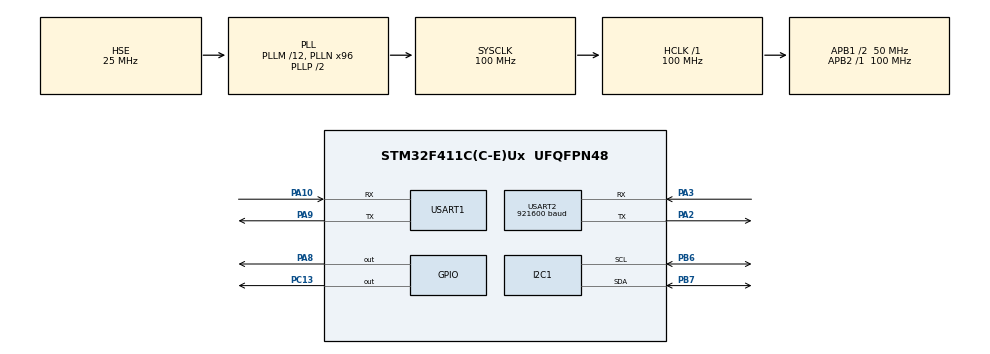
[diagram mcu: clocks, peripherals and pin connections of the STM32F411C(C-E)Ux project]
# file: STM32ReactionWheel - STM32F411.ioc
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I2C1.I2C_Mode=I2C_Fast
Mcu.Family=STM32F4
Mcu.Name=STM32F411C(C-E)Ux
Mcu.Package=UFQFPN48
NVIC.PriorityGroup=NVIC_PRIORITYGROUP_4
PA10.Mode=Asynchronous
PA10.Signal=USART1_RX
PA13.Mode=Trace_Asynchronous_SW
PA13.Signal=SYS_JTMS-SWDIO
PA14.Mode=Trace_Asynchronous_SW
PA14.Signal=SYS_JTCK-SWCLK
PA2.Mode=Asynchronous
PA2.Signal=USART2_TX
PA3.Mode=Asynchronous
PA3.Signal=USART2_RX
PA8.Signal=GPIO_Output
PA9.Mode=Asynchronous
PA9.Signal=USART1_TX
PB3.Mode=Trace_Asynchronous_SW
PB3.Signal=SYS_JTDO-SWO
PB6.Mode=I2C
PB6.Signal=I2C1_SCL
PB7.Mode=I2C
PB7.Signal=I2C1_SDA
PC13-ANTI_TAMP.GPIO_ModeDefaultOutputPP=GPIO_MODE_OUTPUT_OD
PC13-ANTI_TAMP.GPIO_PuPd=GPIO_NOPULL
PC13-ANTI_TAMP.PinState=GPIO_PIN_SET
PC13-ANTI_TAMP.Signal=GPIO_Output
PH0\ -\ OSC_IN.Mode=HSE-External-Oscillator
PH0\ -\ OSC_IN.Signal=RCC_OSC_IN
PH1\ -\ OSC_OUT.Mode=HSE-External-Oscillator
PH1\ -\ OSC_OUT.Signal=RCC_OSC_OUT
ProjectManager.HeapSize=0x200
ProjectManager.StackSize=0x400
ProjectManager.TargetToolchain=STM32CubeIDE
RCC.48MHZClocksFreq_Value=50000000
RCC.AHBFreq_Value=100000000
RCC.APB1CLKDivider=RCC_HCLK_DIV2
RCC.APB1Freq_Value=50000000
RCC.APB1TimFreq_Value=100000000
RCC.APB2Freq_Value=100000000
RCC.APB2TimFreq_Value=100000000
RCC.CortexFreq_Value=100000000
RCC.HCLKFreq_Value=100000000
RCC.HSE_VALUE=25000000
RCC.HSI_VALUE=16000000
RCC.LSE_VALUE=32768
RCC.PLLM=12
RCC.PLLN=96
RCC.PLLSourceVirtual=RCC_PLLSOURCE_HSE
RCC.SYSCLKFreq_VALUE=100000000
RCC.SYSCLKSource=RCC_SYSCLKSOURCE_PLLCLK
RCC.VCOOutputFreq_Value=200000000
STMicroelectronics.X-CUBE-ALGOBUILD.1.3.0.LibraryCcDSPOoLibraryJjDSPOoLibrary=true
USART1.VirtualMode=VM_ASYNC
USART2.BaudRate=921600
USART2.Mode=MODE_TX
USART2.VirtualMode=VM_ASYNC
VP_STMicroelectronics.X-CUBE-ALGOBUILD_VS_DSPOoLibraryJjLibrary_1.3.0_1.3.0.Mode=DSPOoLibraryJjLibrary
board=custom

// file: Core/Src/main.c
/* USER CODE BEGIN Header */
/**
  ******************************************************************************
  * @file           : main.c
  * @brief          : Main program body
  ******************************************************************************
  * @attention
  *
  * Copyright (c) 2023 STMicroelectronics.
  * All rights reserved.
  *
  * This software is licensed under terms that can be found in the LICENSE file
  * in the root directory of this software component.
  * If no LICENSE file comes with this software, it is provided AS-IS.
  *
  ******************************************************************************
  */
/* USER CODE END Header */
#include "main.h"

/* USER CODE BEGIN Includes */
#include "Application.h"
/* USER CODE END Includes */

I2C_HandleTypeDef hi2c1;

UART_HandleTypeDef huart1;
UART_HandleTypeDef huart2;

void SystemClock_Config(void);
static void MX_GPIO_Init(void);
static void MX_I2C1_Init(void);
static void MX_USART2_UART_Init(void);
static void MX_USART1_UART_Init(void);

int main(void)
{

  /* MCU Configuration--------------------------------------------------------*/

  /* Reset of all peripherals, Initializes the Flash interface and the Systick. */
  HAL_Init();

  /* Configure the system clock */
  SystemClock_Config();

  /* Initialize all configured peripherals */
  MX_GPIO_Init();
  MX_I2C1_Init();
  MX_USART2_UART_Init();
  MX_USART1_UART_Init();
  /* USER CODE BEGIN 2 */
  Config_HAL_Bus_t Config_HAL_Bus = {hi2c1, huart2};

  Config_Bus_t Config_Bus;
  Config_Bus = App_Config(Config_HAL_Bus);
  /* USER CODE END 2 */

  /* Infinite loop */
  /* USER CODE BEGIN WHILE */
  while (1)
  {
	  App_Main(Config_Bus);
    /* USER CODE END WHILE */

  }
}

void SystemClock_Config(void)
{
  RCC_OscInitTypeDef RCC_OscInitStruct = {0};
  RCC_ClkInitTypeDef RCC_ClkInitStruct = {0};

  /** Configure the main internal regulator output voltage
  */
  __HAL_RCC_PWR_CLK_ENABLE();
  __HAL_PWR_VOLTAGESCALING_CONFIG(PWR_REGULATOR_VOLTAGE_SCALE1);

  /** Initializes the RCC Oscillators according to the specified parameters
  * in the RCC_OscInitTypeDef structure.
  */
  RCC_OscInitStruct.OscillatorType = RCC_OSCILLATORTYPE_HSE;
  RCC_OscInitStruct.HSEState = RCC_HSE_ON;
  RCC_OscInitStruct.PLL.PLLState = RCC_PLL_ON;
  RCC_OscInitStruct.PLL.PLLSource = RCC_PLLSOURCE_HSE;
  RCC_OscInitStruct.PLL.PLLM = 12;
  RCC_OscInitStruct.PLL.PLLN = 96;
  RCC_OscInitStruct.PLL.PLLP = RCC_PLLP_DIV2;
  RCC_OscInitStruct.PLL.PLLQ = 4;
  if (HAL_RCC_OscConfig(&RCC_OscInitStruct) != HAL_OK)
  {
    Error_Handler();
  }

  /** Initializes the CPU, AHB and APB buses clocks
  */
  RCC_ClkInitStruct.ClockType = RCC_CLOCKTYPE_HCLK|RCC_CLOCKTYPE_SYSCLK
                              |RCC_CLOCKTYPE_PCLK1|RCC_CLOCKTYPE_PCLK2;
  RCC_ClkInitStruct.SYSCLKSource = RCC_SYSCLKSOURCE_PLLCLK;
  RCC_ClkInitStruct.AHBCLKDivider = RCC_SYSCLK_DIV1;
  RCC_ClkInitStruct.APB1CLKDivider = RCC_HCLK_DIV2;
  RCC_ClkInitStruct.APB2CLKDivider = RCC_HCLK_DIV1;

  if (HAL_RCC_ClockConfig(&RCC_ClkInitStruct, FLASH_LATENCY_3) != HAL_OK)
  {
    Error_Handler();
  }
}

static void MX_I2C1_Init(void)
{

  hi2c1.Instance = I2C1;
  hi2c1.Init.ClockSpeed = 400000;
  hi2c1.Init.DutyCycle = I2C_DUTYCYCLE_2;
  hi2c1.Init.OwnAddress1 = 0;
  hi2c1.Init.AddressingMode = I2C_ADDRESSINGMODE_7BIT;
  hi2c1.Init.DualAddressMode = I2C_DUALADDRESS_DISABLE;
  hi2c1.Init.OwnAddress2 = 0;
  hi2c1.Init.GeneralCallMode = I2C_GENERALCALL_DISABLE;
  hi2c1.Init.NoStretchMode = I2C_NOSTRETCH_DISABLE;
  if (HAL_I2C_Init(&hi2c1) != HAL_OK)
  {
    Error_Handler();
  }

}

static void MX_USART1_UART_Init(void)
{

  huart1.Instance = USART1;
  huart1.Init.BaudRate = 115200;
  huart1.Init.WordLength = UART_WORDLENGTH_8B;
  huart1.Init.StopBits = UART_STOPBITS_1;
  huart1.Init.Parity = UART_PARITY_NONE;
  huart1.Init.Mode = UART_MODE_TX_RX;
  huart1.Init.HwFlowCtl = UART_HWCONTROL_NONE;
  huart1.Init.OverSampling = UART_OVERSAMPLING_16;
  if (HAL_UART_Init(&huart1) != HAL_OK)
  {
    Error_Handler();
  }

}

static void MX_USART2_UART_Init(void)
{

  huart2.Instance = USART2;
  huart2.Init.BaudRate = 921600;
  huart2.Init.WordLength = UART_WORDLENGTH_8B;
  huart2.Init.StopBits = UART_STOPBITS_1;
  huart2.Init.Parity = UART_PARITY_NONE;
  huart2.Init.Mode = UART_MODE_TX;
  huart2.Init.HwFlowCtl = UART_HWCONTROL_NONE;
  huart2.Init.OverSampling = UART_OVERSAMPLING_16;
  if (HAL_UART_Init(&huart2) != HAL_OK)
  {
    Error_Handler();
  }

}

static void MX_GPIO_Init(void)
{
  GPIO_InitTypeDef GPIO_InitStruct = {0};

  /* GPIO Ports Clock Enable */
  __HAL_RCC_GPIOC_CLK_ENABLE();
  __HAL_RCC_GPIOH_CLK_ENABLE();
  __HAL_RCC_GPIOA_CLK_ENABLE();
  __HAL_RCC_GPIOB_CLK_ENABLE();

  /*Configure GPIO pin Output Level */
  HAL_GPIO_WritePin(GPIOC, GPIO_PIN_13, GPIO_PIN_SET);

  /*Configure GPIO pin Output Level */
  HAL_GPIO_WritePin(GPIOA, GPIO_PIN_8, GPIO_PIN_RESET);

  /*Configure GPIO pin : PC13 */
  GPIO_InitStruct.Pin = GPIO_PIN_13;
  GPIO_InitStruct.Mode = GPIO_MODE_OUTPUT_OD;
  GPIO_InitStruct.Pull = GPIO_NOPULL;
  GPIO_InitStruct.Speed = GPIO_SPEED_FREQ_LOW;
  HAL_GPIO_Init(GPIOC, &GPIO_InitStruct);

  /*Configure GPIO pin : PA8 */
  GPIO_InitStruct.Pin = GPIO_PIN_8;
  GPIO_InitStruct.Mode = GPIO_MODE_OUTPUT_PP;
  GPIO_InitStruct.Pull = GPIO_NOPULL;
  GPIO_InitStruct.Speed = GPIO_SPEED_FREQ_LOW;
  HAL_GPIO_Init(GPIOA, &GPIO_InitStruct);

}

void Error_Handler(void)
{
  __disable_irq();
  while (1)
  {
  }
}
